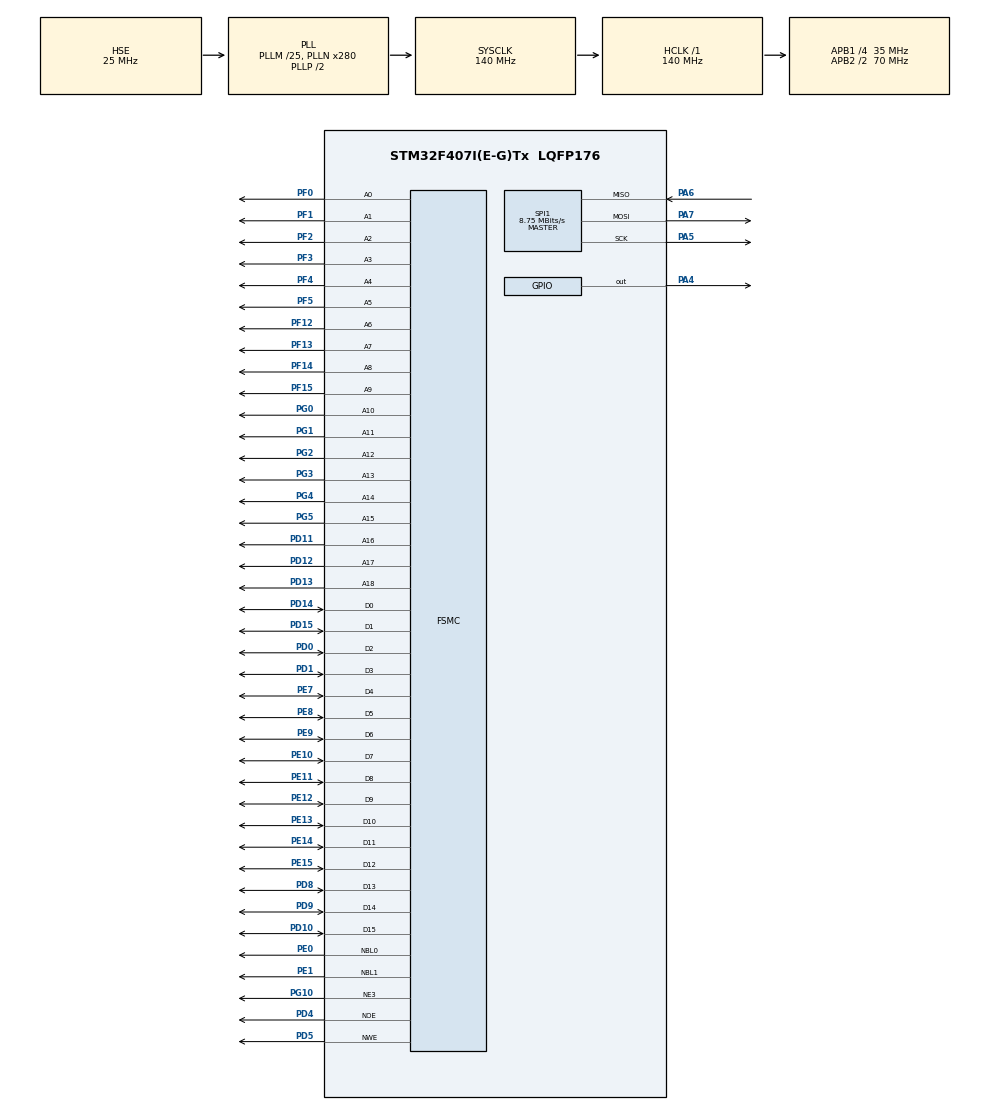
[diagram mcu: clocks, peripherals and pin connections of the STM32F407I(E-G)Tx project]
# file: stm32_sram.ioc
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FSMC.AddressSetupTime1=4
FSMC.BusTurnAroundDuration1=4
FSMC.DataSetupTime1=20
FSMC.WriteOperation1=FSMC_WRITE_OPERATION_ENABLE
Mcu.Family=STM32F4
Mcu.Name=STM32F407I(E-G)Tx
Mcu.Package=LQFP176
NVIC.PriorityGroup=NVIC_PRIORITYGROUP_4
PA4.PinState=GPIO_PIN_SET
PA4.Signal=GPIO_Output
PA5.Mode=Full_Duplex_Master
PA5.Signal=SPI1_SCK
PA6.Mode=Full_Duplex_Master
PA6.Signal=SPI1_MISO
PA7.Mode=Full_Duplex_Master
PA7.Signal=SPI1_MOSI
PD0.GPIO_PuPd=GPIO_PULLUP
PD0.Signal=FSMC_D2_DA2
PD1.GPIO_PuPd=GPIO_PULLUP
PD1.Signal=FSMC_D3_DA3
PD10.GPIO_PuPd=GPIO_PULLUP
PD10.Signal=FSMC_D15_DA15
PD11.GPIO_PuPd=GPIO_PULLUP
PD11.Signal=FSMC_A16_CLE
PD12.GPIO_PuPd=GPIO_PULLUP
PD12.Signal=FSMC_A17_ALE
PD13.GPIO_PuPd=GPIO_PULLUP
PD13.Signal=FSMC_A18
PD14.GPIO_PuPd=GPIO_PULLUP
PD14.Signal=FSMC_D0_DA0
PD15.GPIO_PuPd=GPIO_PULLUP
PD15.Signal=FSMC_D1_DA1
PD4.GPIO_PuPd=GPIO_PULLUP
PD4.Signal=FSMC_NOE
PD5.GPIO_PuPd=GPIO_PULLUP
PD5.Signal=FSMC_NWE
PD8.GPIO_PuPd=GPIO_PULLUP
PD8.Signal=FSMC_D13_DA13
PD9.GPIO_PuPd=GPIO_PULLUP
PD9.Signal=FSMC_D14_DA14
PE0.GPIO_PuPd=GPIO_PULLUP
PE0.Signal=FSMC_NBL0
PE1.GPIO_PuPd=GPIO_PULLUP
PE1.Signal=FSMC_NBL1
PE10.GPIO_PuPd=GPIO_PULLUP
PE10.Signal=FSMC_D7_DA7
PE11.GPIO_PuPd=GPIO_PULLUP
PE11.Signal=FSMC_D8_DA8
PE12.GPIO_PuPd=GPIO_PULLUP
PE12.Signal=FSMC_D9_DA9
PE13.GPIO_PuPd=GPIO_PULLUP
PE13.Signal=FSMC_D10_DA10
PE14.GPIO_PuPd=GPIO_PULLUP
PE14.Signal=FSMC_D11_DA11
PE15.GPIO_PuPd=GPIO_PULLUP
PE15.Signal=FSMC_D12_DA12
PE7.GPIO_PuPd=GPIO_PULLUP
PE7.Signal=FSMC_D4_DA4
PE8.GPIO_PuPd=GPIO_PULLUP
PE8.Signal=FSMC_D5_DA5
PE9.GPIO_PuPd=GPIO_PULLUP
PE9.Signal=FSMC_D6_DA6
PF0.GPIO_PuPd=GPIO_PULLUP
PF0.Signal=FSMC_A0
PF1.GPIO_PuPd=GPIO_PULLUP
PF1.Signal=FSMC_A1
PF12.GPIO_PuPd=GPIO_PULLUP
PF12.Signal=FSMC_A6
PF13.GPIO_PuPd=GPIO_PULLUP
PF13.Signal=FSMC_A7
PF14.GPIO_PuPd=GPIO_PULLUP
PF14.Signal=FSMC_A8
PF15.GPIO_PuPd=GPIO_PULLUP
PF15.Signal=FSMC_A9
PF2.GPIO_PuPd=GPIO_PULLUP
PF2.Signal=FSMC_A2
PF3.GPIO_PuPd=GPIO_PULLUP
PF3.Signal=FSMC_A3
PF4.GPIO_PuPd=GPIO_PULLUP
PF4.Signal=FSMC_A4
PF5.GPIO_PuPd=GPIO_PULLUP
PF5.Signal=FSMC_A5
PG0.GPIO_PuPd=GPIO_PULLUP
PG0.Signal=FSMC_A10
PG1.GPIO_PuPd=GPIO_PULLUP
PG1.Signal=FSMC_A11
PG10.GPIO_PuPd=GPIO_PULLUP
PG10.Mode=NorPsramChipSelect3_1
PG10.Signal=FSMC_NE3
PG2.GPIO_PuPd=GPIO_PULLUP
PG2.Signal=FSMC_A12
PG3.GPIO_PuPd=GPIO_PULLUP
PG3.Signal=FSMC_A13
PG4.GPIO_PuPd=GPIO_PULLUP
PG4.Signal=FSMC_A14
PG5.GPIO_PuPd=GPIO_PULLUP
PG5.Signal=FSMC_A15
PH0-OSC_IN.Mode=HSE-External-Oscillator
PH0-OSC_IN.Signal=RCC_OSC_IN
PH1-OSC_OUT.Mode=HSE-External-Oscillator
PH1-OSC_OUT.Signal=RCC_OSC_OUT
ProjectManager.HeapSize=0x1000
ProjectManager.StackSize=0x1000
ProjectManager.TargetToolchain=EWARM V8.32
RCC.48MHZClocksFreq_Value=70000000
RCC.AHBFreq_Value=140000000
RCC.APB1CLKDivider=RCC_HCLK_DIV4
RCC.APB1Freq_Value=35000000
RCC.APB1TimFreq_Value=70000000
RCC.APB2CLKDivider=RCC_HCLK_DIV2
RCC.APB2Freq_Value=70000000
RCC.APB2TimFreq_Value=140000000
RCC.CortexFreq_Value=140000000
RCC.HCLKFreq_Value=140000000
RCC.HSE_VALUE=25000000
RCC.HSI_VALUE=16000000
RCC.LSE_VALUE=32768
RCC.PLLM=25
RCC.PLLN=280
RCC.PLLSourceVirtual=RCC_PLLSOURCE_HSE
RCC.RCC_RTC_Clock_Source=RCC_RTCCLKSOURCE_LSI
RCC.RCC_RTC_Clock_SourceVirtual=RCC_RTCCLKSOURCE_LSE
RCC.RCC_RTC_Clock_Source_FROM_HSE=RCC_RTCCLKSOURCE_HSE_DIV25
RCC.SYSCLKFreq_VALUE=140000000
RCC.SYSCLKSource=RCC_SYSCLKSOURCE_PLLCLK
RCC.VCOOutputFreq_Value=280000000
SH.FSMC_A0.0=FSMC_A0,19b-a1
SH.FSMC_A1.0=FSMC_A1,19b-a1
SH.FSMC_A10.0=FSMC_A10,19b-a1
SH.FSMC_A11.0=FSMC_A11,19b-a1
SH.FSMC_A12.0=FSMC_A12,19b-a1
SH.FSMC_A13.0=FSMC_A13,19b-a1
SH.FSMC_A14.0=FSMC_A14,19b-a1
SH.FSMC_A15.0=FSMC_A15,19b-a1
SH.FSMC_A16_CLE.0=FSMC_A16,19b-a1
SH.FSMC_A17_ALE.0=FSMC_A17,19b-a1
SH.FSMC_A18.0=FSMC_A18,19b-a1
SH.FSMC_A2.0=FSMC_A2,19b-a1
SH.FSMC_A3.0=FSMC_A3,19b-a1
SH.FSMC_A4.0=FSMC_A4,19b-a1
SH.FSMC_A5.0=FSMC_A5,19b-a1
SH.FSMC_A6.0=FSMC_A6,19b-a1
SH.FSMC_A7.0=FSMC_A7,19b-a1
SH.FSMC_A8.0=FSMC_A8,19b-a1
SH.FSMC_A9.0=FSMC_A9,19b-a1
SH.FSMC_D0_DA0.0=FSMC_D0,16b-d1
SH.FSMC_D10_DA10.0=FSMC_D10,16b-d1
SH.FSMC_D11_DA11.0=FSMC_D11,16b-d1
SH.FSMC_D12_DA12.0=FSMC_D12,16b-d1
SH.FSMC_D13_DA13.0=FSMC_D13,16b-d1
SH.FSMC_D14_DA14.0=FSMC_D14,16b-d1
SH.FSMC_D15_DA15.0=FSMC_D15,16b-d1
SH.FSMC_D1_DA1.0=FSMC_D1,16b-d1
SH.FSMC_D2_DA2.0=FSMC_D2,16b-d1
SH.FSMC_D3_DA3.0=FSMC_D3,16b-d1
SH.FSMC_D4_DA4.0=FSMC_D4,16b-d1
SH.FSMC_D5_DA5.0=FSMC_D5,16b-d1
SH.FSMC_D6_DA6.0=FSMC_D6,16b-d1
SH.FSMC_D7_DA7.0=FSMC_D7,16b-d1
SH.FSMC_D8_DA8.0=FSMC_D8,16b-d1
SH.FSMC_D9_DA9.0=FSMC_D9,16b-d1
SH.FSMC_NBL0.0=FSMC_NBL0,2ByteEnable1
SH.FSMC_NBL1.0=FSMC_NBL1,2ByteEnable1
SH.FSMC_NOE.0=FSMC_NOE,Sram1
SH.FSMC_NWE.0=FSMC_NWE,Sram1
SPI1.BaudRatePrescaler=SPI_BAUDRATEPRESCALER_8
SPI1.CLKPhase=SPI_PHASE_1EDGE
SPI1.CLKPolarity=SPI_POLARITY_LOW
SPI1.CalculateBaudRate=8.75 MBits/s
SPI1.Direction=SPI_DIRECTION_2LINES
SPI1.Mode=SPI_MODE_MASTER
SPI1.VirtualType=VM_MASTER
board=custom

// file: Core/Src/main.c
/* USER CODE BEGIN Header */
/**
  ******************************************************************************
  * @file           : main.c
  * @brief          : Main program body
  ******************************************************************************
  * @attention
  *
  * <h2><center>&copy; Copyright (c) 2021 STMicroelectronics.
  * All rights reserved.</center></h2>
  *
  * This software component is licensed by ST under BSD 3-Clause license,
  * the "License"; You may not use this file except in compliance with the
  * License. You may obtain a copy of the License at:
  *                        opensource.org/licenses/BSD-3-Clause
  *
  ******************************************************************************
  */
/* USER CODE END Header */
#include "main.h"

SPI_HandleTypeDef hspi1;

SRAM_HandleTypeDef hsram1;

void SystemClock_Config(void);
static void MX_GPIO_Init(void);
static void MX_FSMC_Init(void);
static void MX_SPI1_Init(void);

int main(void)
{

  /* MCU Configuration--------------------------------------------------------*/

  /* Reset of all peripherals, Initializes the Flash interface and the Systick. */
  HAL_Init();

  /* Configure the system clock */
  SystemClock_Config();

  /* Initialize all configured peripherals */
  MX_GPIO_Init();
  MX_FSMC_Init();
  MX_SPI1_Init();
  /* USER CODE BEGIN 2 */
	W25qxx_Init();

  /* USER CODE END 2 */

  /* Infinite loop */
  /* USER CODE BEGIN WHILE */
  memset((char *)0x68000000,0x0,0x1000);

  volatile char *p=(char *)0x68000000;
  volatile unsigned 	int *pi=(unsigned int *)0x68000000;
  volatile int err=0;
  unsigned int i;
  for(i=0;i<0x100000/4;i++){

    pi[i]=i;
  }

	for(i=0;i<0x100000/4;i++){

    if(pi[i]!=i)
			err++;
  }

  while (1)
  {
    /* USER CODE END WHILE */

  }
}

void SystemClock_Config(void)
{
  RCC_OscInitTypeDef RCC_OscInitStruct = {0};
  RCC_ClkInitTypeDef RCC_ClkInitStruct = {0};

  /** Configure the main internal regulator output voltage
  */
  __HAL_RCC_PWR_CLK_ENABLE();
  __HAL_PWR_VOLTAGESCALING_CONFIG(PWR_REGULATOR_VOLTAGE_SCALE1);
  /** Initializes the RCC Oscillators according to the specified parameters
  * in the RCC_OscInitTypeDef structure.
  */
  RCC_OscInitStruct.OscillatorType = RCC_OSCILLATORTYPE_HSE;
  RCC_OscInitStruct.HSEState = RCC_HSE_ON;
  RCC_OscInitStruct.PLL.PLLState = RCC_PLL_ON;
  RCC_OscInitStruct.PLL.PLLSource = RCC_PLLSOURCE_HSE;
  RCC_OscInitStruct.PLL.PLLM = 25;
  RCC_OscInitStruct.PLL.PLLN = 280;
  RCC_OscInitStruct.PLL.PLLP = RCC_PLLP_DIV2;
  RCC_OscInitStruct.PLL.PLLQ = 4;
  if (HAL_RCC_OscConfig(&RCC_OscInitStruct) != HAL_OK)
  {
    Error_Handler();
  }
  /** Initializes the CPU, AHB and APB buses clocks
  */
  RCC_ClkInitStruct.ClockType = RCC_CLOCKTYPE_HCLK|RCC_CLOCKTYPE_SYSCLK
                              |RCC_CLOCKTYPE_PCLK1|RCC_CLOCKTYPE_PCLK2;
  RCC_ClkInitStruct.SYSCLKSource = RCC_SYSCLKSOURCE_PLLCLK;
  RCC_ClkInitStruct.AHBCLKDivider = RCC_SYSCLK_DIV1;
  RCC_ClkInitStruct.APB1CLKDivider = RCC_HCLK_DIV4;
  RCC_ClkInitStruct.APB2CLKDivider = RCC_HCLK_DIV2;

  if (HAL_RCC_ClockConfig(&RCC_ClkInitStruct, FLASH_LATENCY_4) != HAL_OK)
  {
    Error_Handler();
  }
}

static void MX_SPI1_Init(void)
{

  /* SPI1 parameter configuration*/
  hspi1.Instance = SPI1;
  hspi1.Init.Mode = SPI_MODE_MASTER;
  hspi1.Init.Direction = SPI_DIRECTION_2LINES;
  hspi1.Init.DataSize = SPI_DATASIZE_8BIT;
  hspi1.Init.CLKPolarity = SPI_POLARITY_LOW;
  hspi1.Init.CLKPhase = SPI_PHASE_1EDGE;
  hspi1.Init.NSS = SPI_NSS_SOFT;
  hspi1.Init.BaudRatePrescaler = SPI_BAUDRATEPRESCALER_8;
  hspi1.Init.FirstBit = SPI_FIRSTBIT_MSB;
  hspi1.Init.TIMode = SPI_TIMODE_DISABLE;
  hspi1.Init.CRCCalculation = SPI_CRCCALCULATION_DISABLE;
  hspi1.Init.CRCPolynomial = 10;
  if (HAL_SPI_Init(&hspi1) != HAL_OK)
  {
    Error_Handler();
  }

}

static void MX_GPIO_Init(void)
{
  GPIO_InitTypeDef GPIO_InitStruct = {0};

  /* GPIO Ports Clock Enable */
  __HAL_RCC_GPIOF_CLK_ENABLE();
  __HAL_RCC_GPIOH_CLK_ENABLE();
  __HAL_RCC_GPIOA_CLK_ENABLE();
  __HAL_RCC_GPIOG_CLK_ENABLE();
  __HAL_RCC_GPIOE_CLK_ENABLE();
  __HAL_RCC_GPIOD_CLK_ENABLE();

  /*Configure GPIO pin Output Level */
  HAL_GPIO_WritePin(GPIOA, GPIO_PIN_4, GPIO_PIN_SET);

  /*Configure GPIO pin : PA4 */
  GPIO_InitStruct.Pin = GPIO_PIN_4;
  GPIO_InitStruct.Mode = GPIO_MODE_OUTPUT_PP;
  GPIO_InitStruct.Pull = GPIO_NOPULL;
  GPIO_InitStruct.Speed = GPIO_SPEED_FREQ_LOW;
  HAL_GPIO_Init(GPIOA, &GPIO_InitStruct);

}

/* FSMC initialization function */
static void MX_FSMC_Init(void)
{

  FSMC_NORSRAM_TimingTypeDef Timing = {0};

  /** Perform the SRAM1 memory initialization sequence
  */
  hsram1.Instance = FSMC_NORSRAM_DEVICE;
  hsram1.Extended = FSMC_NORSRAM_EXTENDED_DEVICE;
  /* hsram1.Init */
  hsram1.Init.NSBank = FSMC_NORSRAM_BANK3;
  hsram1.Init.DataAddressMux = FSMC_DATA_ADDRESS_MUX_DISABLE;
  hsram1.Init.MemoryType = FSMC_MEMORY_TYPE_SRAM;
  hsram1.Init.MemoryDataWidth = FSMC_NORSRAM_MEM_BUS_WIDTH_16;
  hsram1.Init.BurstAccessMode = FSMC_BURST_ACCESS_MODE_DISABLE;
  hsram1.Init.WaitSignalPolarity = FSMC_WAIT_SIGNAL_POLARITY_LOW;
  hsram1.Init.WrapMode = FSMC_WRAP_MODE_DISABLE;
  hsram1.Init.WaitSignalActive = FSMC_WAIT_TIMING_BEFORE_WS;
  hsram1.Init.WriteOperation = FSMC_WRITE_OPERATION_ENABLE;
  hsram1.Init.WaitSignal = FSMC_WAIT_SIGNAL_DISABLE;
  hsram1.Init.ExtendedMode = FSMC_EXTENDED_MODE_DISABLE;
  hsram1.Init.AsynchronousWait = FSMC_ASYNCHRONOUS_WAIT_DISABLE;
  hsram1.Init.WriteBurst = FSMC_WRITE_BURST_DISABLE;
  hsram1.Init.PageSize = FSMC_PAGE_SIZE_NONE;
  /* Timing */
  Timing.AddressSetupTime = 4;
  Timing.AddressHoldTime = 15;
  Timing.DataSetupTime = 20;
  Timing.BusTurnAroundDuration = 4;
  Timing.CLKDivision = 16;
  Timing.DataLatency = 17;
  Timing.AccessMode = FSMC_ACCESS_MODE_A;
  /* ExtTiming */

  if (HAL_SRAM_Init(&hsram1, &Timing, NULL) != HAL_OK)
  {
    Error_Handler( );
  }

}

void Error_Handler(void)
{
  __disable_irq();
  while (1)
  {
  }
}

/************************ (C) COPYRIGHT STMicroelectronics *****END OF FILE****/
